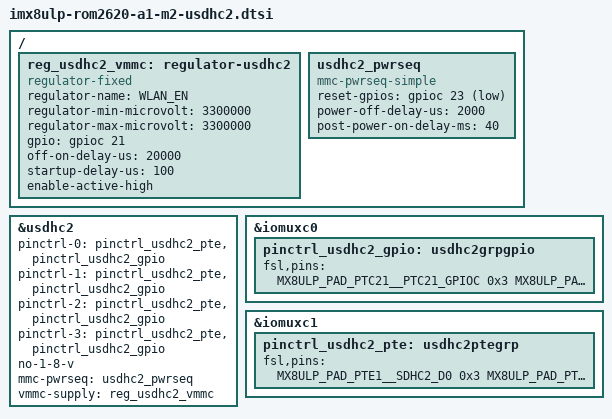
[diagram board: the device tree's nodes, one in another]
/ {
	reg_usdhc2_vmmc: regulator-usdhc2 {
		compatible = "regulator-fixed";
		regulator-name = "WLAN_EN";
		regulator-min-microvolt = <3300000>;
		regulator-max-microvolt = <3300000>;
		gpio = <&gpioc 21 GPIO_ACTIVE_HIGH>;
		off-on-delay-us = <20000>;
		startup-delay-us = <100>;
		enable-active-high;
	};

	usdhc2_pwrseq: usdhc2_pwrseq {
		compatible = "mmc-pwrseq-simple";
		reset-gpios = <&gpioc 23 GPIO_ACTIVE_LOW>; /* SDIO card */
		power-off-delay-us = <2000>;
		post-power-on-delay-ms = <40>;
	};
};

&usdhc2 {
	pinctrl-names = "default", "state_100mhz", "state_200mhz", "sleep";
	pinctrl-0 = <&pinctrl_usdhc2_pte>, <&pinctrl_usdhc2_gpio>;
	pinctrl-1 = <&pinctrl_usdhc2_pte>, <&pinctrl_usdhc2_gpio>;
	pinctrl-2 = <&pinctrl_usdhc2_pte>, <&pinctrl_usdhc2_gpio>;
	pinctrl-3 = <&pinctrl_usdhc2_pte>, <&pinctrl_usdhc2_gpio>;
	no-1-8-v;
	mmc-pwrseq = <&usdhc2_pwrseq>;
	vmmc-supply = <&reg_usdhc2_vmmc>;
	/delete-property/ max-frequency;
	/delete-property/ wakeup-source;
	/delete-node/ wifi_wake_host;
};

&iomuxc0 {
	pinctrl_usdhc2_gpio: usdhc2grpgpio {
		fsl,pins = <
			MX8ULP_PAD_PTC21__PTC21_GPIOC	0x3 /* M2_SDIO_RST */
			MX8ULP_PAD_PTC23__PTC23_GPIOC	0x3 /* W_DISABLE1 */
		>;
	};
};

&iomuxc1 {
	pinctrl_usdhc2_pte: usdhc2ptegrp {
		fsl,pins = <
			MX8ULP_PAD_PTE1__SDHC2_D0	0x3
			MX8ULP_PAD_PTE0__SDHC2_D1	0x3
			MX8ULP_PAD_PTE5__SDHC2_D2	0x3
			MX8ULP_PAD_PTE4__SDHC2_D3	0x3
			MX8ULP_PAD_PTE2__SDHC2_CLK	0x10002
			MX8ULP_PAD_PTE3__SDHC2_CMD	0x3
			MX8ULP_PAD_PTF26__SDHC2_RESET_B	0x3
			MX8ULP_PAD_PTF27__SDHC2_WP	0x2
			MX8ULP_PAD_PTF28__SDHC2_CD	0x3
		>;
	};
};
